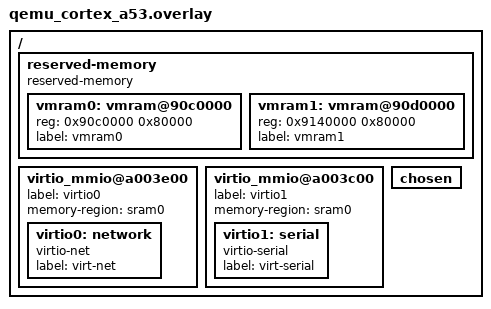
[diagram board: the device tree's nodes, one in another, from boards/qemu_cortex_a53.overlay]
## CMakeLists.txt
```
# SPDX-License-Identifier: Apache-2.0

cmake_minimum_required(VERSION 3.13.1)

list(APPEND QEMU_EXTRA_FLAGS -device virtio-serial-device)
list(APPEND QEMU_EXTRA_FLAGS -chardev socket,path=/tmp/foo,server=on,wait=off,id=foo)
list(APPEND QEMU_EXTRA_FLAGS -device virtconsole,chardev=foo)
find_package(Zephyr REQUIRED HINTS $ENV{ZEPHYR_BASE})
project(hello_world)

zephyr_compile_definitions(METAL_MAX_DEVICE_REGIONS=2)

target_sources(app PRIVATE src/main.c)
```

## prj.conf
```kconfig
CONFIG_ASSERT=y
CONFIG_VIRTIO=y
CONFIG_VIRTIO_MMIO=y
CONFIG_VIRTIO_SERIAL=n
CONFIG_VIRTIO_NETWORK=y
CONFIG_BOOT_BANNER=n
#network seems to depend on a RNG
CONFIG_TEST_RANDOM_GENERATOR=y
CONFIG_TIMER_RANDOM_GENERATOR=y
CONFIG_NET_QEMU_USER=y
CONFIG_NETWORKING=y
CONFIG_NET_IPV6=n
CONFIG_NET_IPV4=y
CONFIG_NET_CONFIG_NEED_IPV4=y
CONFIG_NET_DHCPV4=y
CONFIG_OPENAMP=y
CONFIG_LIBMETAL=y
CONFIG_SHELL=y
CONFIG_NET_SHELL=y
CONFIG_HEAP_MEM_POOL_SIZE=131072
```

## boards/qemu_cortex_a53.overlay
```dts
/{

	reserved-memory {
		compatible = "reserved-memory";
		#address-cells = <1>;
		#size-cells = <1>;
		status = "okay";
		ranges;

		vmram0: vmram@90c0000 {
			status = "okay";
			reg = < 0x90c0000 0x80000 >;
			device_type = "memory";
			label = "vmram0";
		};

		vmram1: vmram@90d0000 {
			status = "okay";
			reg = < 0x9140000 0x80000 >;
			device_type = "memory";
			label = "vmram1";
		};
	};

	virtio_mmio@a003e00 {
		status = "okay";
		label = "virtio0";
		memory-region = <&sram0>;
		virtio0: network {
			label = "virt-net";
			compatible = "virtio-net";
		};
	};

	virtio_mmio@a003c00 {
		status = "okay";
		label = "virtio1";
		memory-region = <&sram0>;
		virtio1: serial {
			label = "virt-serial";
			compatible = "virtio-serial";
		};
	};


	chosen {
//		zephyr,console = &virtio1;
//		zephyr,shell-uart = &virtio1;
	};

};

/delete-node/ &eth0;
```

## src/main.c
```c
/*
 * Copyright (c) 2012-2014 Wind River Systems, Inc.
 *
 * SPDX-License-Identifier: Apache-2.0
 */

#include <zephyr/kernel.h>
#include <zephyr/sys/printk.h>
#include <zephyr/init.h>
#include <zephyr/net/net_if.h>
#include <zephyr/net/net_core.h>
#include <metal/device.h>

int main(void)
{
	printk("Hello World! %s\n", CONFIG_BOARD);
        struct net_if *iface;

#ifdef CONFIG_NETWORKING
        iface = net_if_get_default();
#endif

#ifdef CONFIG_NET_DHCPV4
        net_dhcpv4_start(iface);
#endif
	return 0;
}

#define PRINTK_TEST(level) \
int _test_##level()\
{\
	printk("%s()\n",__FUNCTION__);\
	return 0;\
}\
SYS_INIT(_test_##level,level, 99);

int init_metal()
{
	int32_t err;
	struct metal_init_params metal_params = METAL_INIT_DEFAULTS;
	metal_params.log_level = METAL_LOG_DEBUG;

	err = metal_init(&metal_params);
	if (err) {
		metal_log(METAL_LOG_ERROR, "metal_init: failed - error code %d\n", err);
		return -ENODEV;
	}

	return 0;
}
SYS_INIT(init_metal, PRE_KERNEL_1, 49);

PRINTK_TEST(PRE_KERNEL_1)
PRINTK_TEST(PRE_KERNEL_2)
PRINTK_TEST(POST_KERNEL)
PRINTK_TEST(APPLICATION)

void printk_timer_expired(struct k_timer *timer)
{
	printk("%s()\n",__FUNCTION__);
}

K_TIMER_DEFINE(printk_test_timer, printk_timer_expired, NULL);

int printk_timer_start()
{
	k_timer_start(& printk_test_timer, K_MSEC(10), K_SECONDS(10));
	return 0;
}

//SYS_INIT(printk_timer_start,PRE_KERNEL_1, 99);
```
